# cslr_fsync register map
Vendor: Texas Instruments
Peripheral module from a debugger description file.
Registers are 32-bit, access per field, reset 0x0 unless marked. A register's access mark holds for its fields unless they carry their own. Offsets are as the file gives them; lines under a group give offsets from that group; [hi:lo] are bit positions; {n}, {i} and the like mark numbered series; 'fields as' and 'values as' point back to an identical list; <NAME> marks a mode.

## FSYNC — Frame Synchronization Peripheral
0x00 PID ro — Peripheral Identification Register{FSYNC_PID}
  [31:0] REG
0x80 ERR_INT_SRC_RAW ro — FSYNC ERR INT SRC RAW Register {FSYNC_ERR_INT_SRC_RAW}
  [14:0] ERR — Shows unmasked source state of interrupts
0x84 ERR_MASK_STAT_0 ro — FSYNC ERR MASK STATUS 0 Register {FSYNC_ERR_MASK_STAT_0}
  [14:0] ERR — Shows masked source state of interrupts
0x88 ERR_MASK_STAT_1 ro — FSYNC ERR MASK STATUS 1 Register {FSYNC_ERR_MASK_STAT_1}
  [14:0] ERR — Shows masked source state of interrupts
0x8C ERR_SET_MASK_0 — FSYNC ERR SET MASK 0 Register {FSYNC_ERR_SET_MASK_0}
  [14:0] ERR wo — Error set mask 0
0x90 ERR_SET_MASK_1 — FSYNC ERR SET MASK 1 Register {FSYNC_ERR_SET_MASK_1}
  [14:0] ERR wo — Error set mask 1
0x94 ERR_CLEAR_MASK_0 — FSYNC ERR CLEAR MASK 0 Register {FSYNC_ERR_CLEAR_MASK_0}
  [14:0] ERR wo — Error clear mask 0
0x98 ERR_CLEAR_MASK_1 — FSYNC ERR CLEAR MASK 1 Register {FSYNC_ERR_SET_MASK_1}
  [14:0] ERR wo — Error clear mask 1
0x9C ERR_INT_MASK_0 ro — FSYNC ERR INT MASK 0 Register {FSYNC_ERR_INT_MASK_0}
  [14:0] ERR — Error interrupt mask 0
0xA0 ERR_INT_MASK_1 ro — FSYNC ERR INT MASK 1 Register {FSYNC_ERR_INT_MASK_1}
  [14:0] ERR — Error interrupt mask 1
0xA4 ERR_INT_SET — FSYNC ERR INT SET Register {FSYNC_ERR_INT_SET}
  [14:0] ERR wo — Error interrupt set
0xA8 ERR_INT_CLEAR — FSYNC ERR INT CLEAR Register {FSYNC_ERR_INT_CLEAR}
  [14:0] ERR wo — Error interrupt clear
0xAC ERR_END_OF_INT — FSYNC ERR END 0F INT Register {FSYNC_ERR_END_OF_INT}
  [14:0] ERR rw — Error end of interrupt
0xB0 SCRATCH rw — FSYNC Scratch Register {FSYNC_SCRATCH}
  [31:0] SCRATCH — Dummy location for test
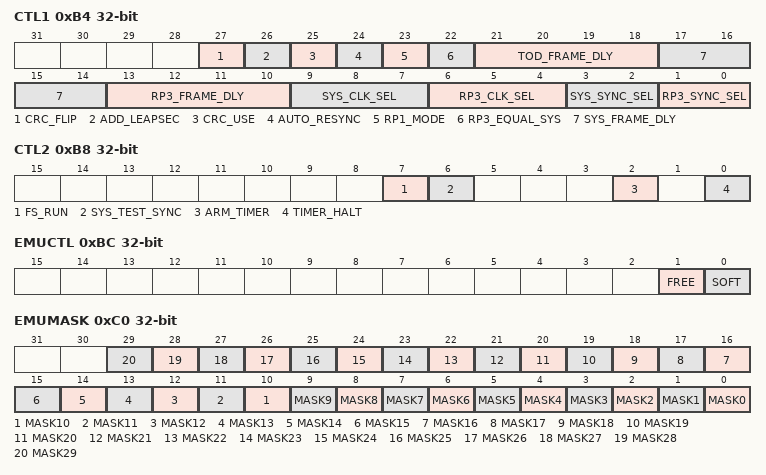
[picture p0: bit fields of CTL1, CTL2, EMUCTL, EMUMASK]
0xB4 CTL1 — FSYNC Control Register 1 {FSYNC_CTL1}
  [27] CRC_FLIP rw — Timer start
    0=MS_1ST (CRC bit 15 received first); 1=LS_1ST (CRC bit 0 received first)
  [26] ADD_LEAPSEC rw — Timer halt
    0=NO_ADD (Do not add leapseconds to TOD); 1=ADD (Add leapseconds to TOD timer)
  [25] CRC_USE rw — CRC use enable
    0=DISABLE (Use sync_burst message regardless of CRC pass/fail); 1=ENABLE (Discard sync_burst message on CRC fail)
  [24] AUTO_RESYNC rw — Automatic resync enable
    0=DISABLE (Disable auto-resync); 1=ENABLE (Enable auto-resync)
  [23] RP1_MODE rw — RP1 operation mode enable
    0=DISABLE (Disable RP1 synchronization); 1=ENABLE (Enable RP1 synchronization)
  [22] RP3_EQUAL_SYS rw — System timer only selection
    0=FALSE (System timer is separate from RP3 timer); 1=TRUE (System timer is the same as the RP3 timer)
  [21:18] TOD_FRAME_DLY rw — Time-of-Day frame syncronization delay
  [17:14] SYS_FRAME_DLY rw — System frame syncronization delay
  [13:10] RP3_FRAME_DLY rw — RP3 frame syncronization delay
  [9:7] SYS_CLK_SEL rw — System timer clock source selection
    0=MOD_CLK (Internal module clock (CPU/3)); 1=MOD_CLK3 (Module clock / 3 (CPU/9)); 2=FSYNC_CLK (Frame sync clock input); 3=UMTS_CLK (UMTS clock input); 4=TRT_CLK (TRT clock input)
  [6:4] RP3_CLK_SEL rw — RP3 timer clock source selection
    values as SYS_CLK_SEL
  [3:2] SYS_SYNC_SEL rw — System timer synchronization selection
    0=FRAME_BURST (OBSAI RP1 differential FRAME_BURST); 1=UMTS_SYNC (UMTS_SYNC input); 2=TRT (TRT input); 3=SYS_TEST (System Test input)
  [1:0] RP3_SYNC_SEL rw — RP3 timer synchronization selcetion
    values as SYS_SYNC_SEL
0xB8 CTL2 — FSYNC Control Register 2 {FSYNC_CTL2}
  [7] FS_RUN ro — FS Running
    0=NO_RUN (No effect); 1=RUN (FS run)
  [6] SYS_TEST_SYNC rw — System test sync
    0=NO_PULSE (No effect); 1=PULSE (Create internal sync pulse)
  [2] ARM_TIMER rw — Arm the RP3 timer to start when synchronization occurs
    0=NO_ARM (No effect); 1=ARM (Arm Timers)
  [0] TIMER_HALT rw
    0=NO_HALT (No effect); 1=HALT (Halt RP3 and system timers)
0xBC EMUCTL — FSYNC Emulation Control Register {FSYNC_EMUCTL}
  [1] FREE rw — Free run
    0=SUSPEND (Halt on emulation halt); 1=FREERUN (Ignore emulation halt)
  [0] SOFT rw — Soft halt
    0=SOFTHALT (Free run timers, disable some events with emu mask); 1=HARDHALT (Halt all timers and events)
0xC0 EMUMASK — FSYNC Emulation Mask Register {FSYNC_EMUMASK}
  [n] MASK{n} rw (n=0..29) — Mask for Event {n}
    0=FALSE (Do not mask event {n}); 1=TRUE (Mask event {n})
0xC4 RP1TS — FSYNC RP1 Type Select Register {FSYNC_RP1TS}
  [7:0] RP1_TYPE rw
    2=WCDMA_FDD (WCDMA or FDD); 7=CDMA2000
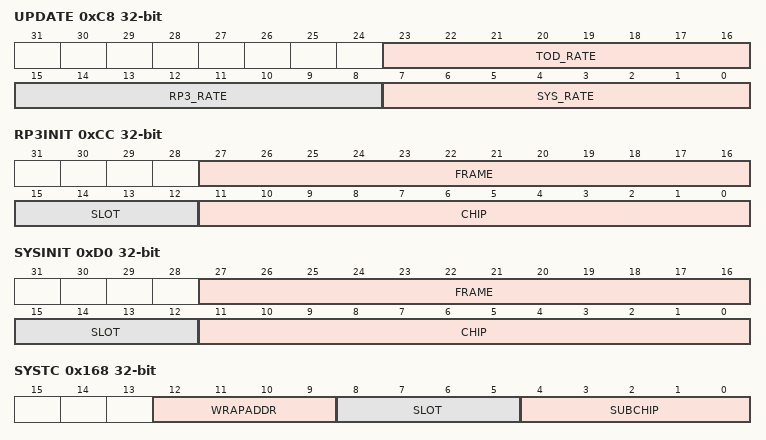
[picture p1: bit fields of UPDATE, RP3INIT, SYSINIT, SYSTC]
0xC8 UPDATE — FSYNC Update Register {FSYNC_UPDATE}
  [23:16] TOD_RATE rw — System Frame Update Rate
  [15:8] RP3_RATE rw — RP3 Frame Update Rate
  [7:0] SYS_RATE rw — TOD Frame Update Rate
0xCC RP3INIT rw — FSYNC RP3 Init Register {FSYNC_RP3INIT}
  [27:16] FRAME — System tmer frame count
  [15:12] SLOT — System timer slot count
  [11:0] CHIP — System timer chip count
0xD0 SYSINIT rw — FSYNC System Init Register {FSYNC_SYSINIT}
  fields as RP3INIT
0x100 RP3TC0 ro — FSYNC RP3 Terminal Count Entry {FSYNC_RP3TC0}
  [11:0] TCOUNT — Terminal Count RAM for chip count
0x104 RP3TC1 ro — FSYNC RP3 Terminal Count Entry {FSYNC_RP3TC1}
  [11:0] TCOUNT — Terminal Count RAM for chip count
0x108 RP3TC2 ro — FSYNC RP3 Terminal Count Entry {FSYNC_RP3TC2}
  [11:0] TCOUNT — Terminal Count RAM for chip count
0x10C RP3TC3 ro — FSYNC RP3 Terminal Count Entry {FSYNC_RP3TC3}
  [11:0] TCOUNT — Terminal Count RAM for chip count
0x110 RP3TC4 ro — FSYNC RP3 Terminal Count Entry {FSYNC_RP3TC4}
  [11:0] TCOUNT — Terminal Count RAM for chip count
0x114 RP3TC5 ro — FSYNC RP3 Terminal Count Entry {FSYNC_RP3TC5}
  [11:0] TCOUNT — Terminal Count RAM for chip count
0x118 RP3TC6 ro — FSYNC RP3 Terminal Count Entry {FSYNC_RP3TC6}
  [11:0] TCOUNT — Terminal Count RAM for chip count
0x11C RP3TC7 ro — FSYNC RP3 Terminal Count Entry {FSYNC_RP3TC7}
  [11:0] TCOUNT — Terminal Count RAM for chip count
0x120 RP3TC8 ro — FSYNC RP3 Terminal Count Entry {FSYNC_RP3TC8}
  [11:0] TCOUNT — Terminal Count RAM for chip count
0x124 RP3TC9 ro — FSYNC RP3 Terminal Count Entry {FSYNC_RP3TC9}
  [11:0] TCOUNT — Terminal Count RAM for chip count
0x128 TOD1 ro — FSYNC TOD Capture Register 1 {FSYNC_TOD1}
  [31:0] TOD_LS — TOD Capture LSBs
0x12C TOD2 ro — FSYNC TOD Capture Register2 {FSYNC_TOD2}
  [31:0] TOD_MS — TOD Capture MSBs
0x130 RP31 ro — FSYNC RP3 Capture Register 1 {FSYNC_RP31}
  [31:0] RP3_LS — RP3 Capture LSBs
0x134 RP32 ro — FSYNC RP3 Capture Register 2 {FSYNC_RP32}
  [31:0] RP3_MS — RP3 Capture MSBs
0x138 SYS1 ro — FSYNC SYS Capture Register 1 {FSYNC_SYS1}
  [31:0] SYS_LS — SYS Capture LSBs
0x13C SYS2 ro — FSYNC SYS Capture Register 2 {FSYNC_SYS2}
  [31:0] SYS_MS — SYS Capture MSBs
0x140 SYSTC0 ro — FSYNC System Terminal Count Entry {FSYNC_SYSTC0}
  [11:0] TCOUNT — Terminal Count RAM for chip count
0x144 SYSTC1 ro — FSYNC System Terminal Count Entry {FSYNC_SYSTC1}
  [11:0] TCOUNT — Terminal Count RAM for chip count
0x148 SYSTC2 ro — FSYNC System Terminal Count Entry {FSYNC_SYSTC2}
  [11:0] TCOUNT — Terminal Count RAM for chip count
0x14C SYSTC3 ro — FSYNC System Terminal Count Entry {FSYNC_SYSTC3}
  [11:0] TCOUNT — Terminal Count RAM for chip count
0x150 SYSTC4 ro — FSYNC System Terminal Count Entry {FSYNC_SYSTC4}
  [11:0] TCOUNT — Terminal Count RAM for chip count
0x154 SYSTC5 ro — FSYNC System Terminal Count Entry {FSYNC_SYSTC5}
  [11:0] TCOUNT — Terminal Count RAM for chip count
0x158 SYSTC6 ro — FSYNC System Terminal Count Entry {FSYNC_SYSTC6}
  [11:0] TCOUNT — Terminal Count RAM for chip count
0x15C SYSTC7 ro — FSYNC System Terminal Count Entry {FSYNC_SYSTC7}
  [11:0] TCOUNT — Terminal Count RAM for chip count
0x160 SYSTC8 ro — FSYNC System Terminal Count Entry {FSYNC_SYSTC8}
  [11:0] TCOUNT — Terminal Count RAM for chip count
0x164 SYSTC9 ro — FSYNC System Terminal Count Entry {FSYNC_SYSTC9}
  [11:0] TCOUNT — Terminal Count RAM for chip count
0x168 SYSTC — FSYNC System Terminal Count Register {FSYNC_SYSTC}
  [12:9] WRAPADDR rw — Chip TC RAM wrap address
  [8:5] SLOT rw
  [4:0] SUBCHIP rw — Sub-chip (input clock divider)
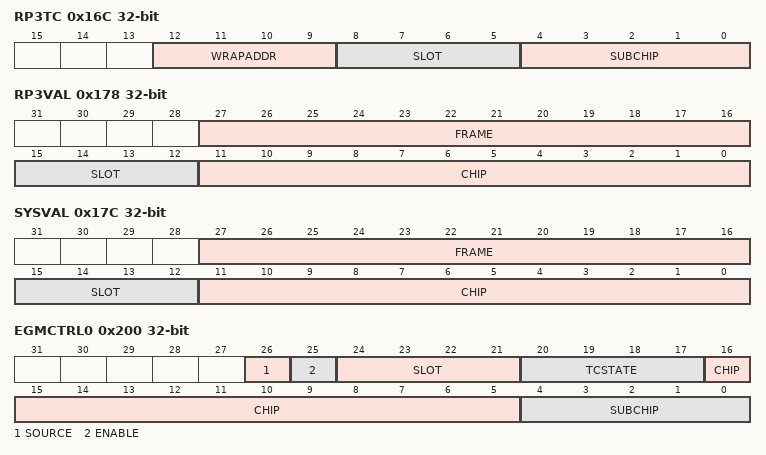
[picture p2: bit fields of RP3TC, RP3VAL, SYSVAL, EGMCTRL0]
0x16C RP3TC — FSYNC System Terminal Count Register {FSYNC_RP3TC}
  fields as SYSTC
0x170 TYPE ro — FSYNC Type Capture Register {FSYNC_TYPE}
  [7:0] TYPE — RP1 Type Capture
0x174 TODVAL ro — FSYNC TOD VAL Register {FSYNC_TODVAL}
  [31:0] VALUE — Read the current value of the TOD timer in secs
0x178 RP3VAL ro — FSYNC RP3 VAL Register {FSYNC_RP3VAL}
  fields as RP3INIT
0x17C SYSVAL ro — FSYNC System VAL Register {FSYNC_SYSVAL}
  fields as RP3INIT
0x200 EGMCTRL0 — FSYNC Mask Event Generator Control Register {FSYNC_EGMCTRL0}
  [26] SOURCE rw — Event Source
    0=SYS (System timer with system sub-chip clock); 1=RP3 (RP3 timer with RP3 sub-chip clock)
  [25] ENABLE rw — Event Enable
    0=DISABLE (Disable Event); 1=ENABLE (Enable Event)
  [24:21] SLOT rw — Slot compare value
  [20:17] TCSTATE rw — Chip TC state compare value
  [16:5] CHIP rw — Chip compare value
  [4:0] SUBCHIP rw — Sub-chip compare value
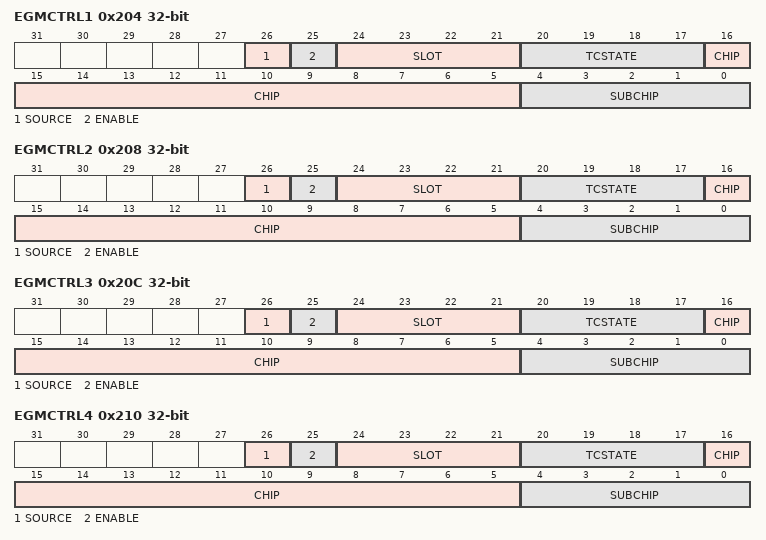
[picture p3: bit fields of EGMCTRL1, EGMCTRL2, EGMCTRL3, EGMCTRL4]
0x204 EGMCTRL1 — FSYNC Mask Event Generator Control Register {FSYNC_EGMCTRL1}
  fields as EGMCTRL0
0x208 EGMCTRL2 — FSYNC Mask Event Generator Control Register {FSYNC_EGMCTRL2}
  fields as EGMCTRL0
0x20C EGMCTRL3 — FSYNC Mask Event Generator Control Register {FSYNC_EGMCTRL3}
  fields as EGMCTRL0
0x210 EGMCTRL4 — FSYNC Mask Event Generator Control Register {FSYNC_EGMCTRL4}
  fields as EGMCTRL0
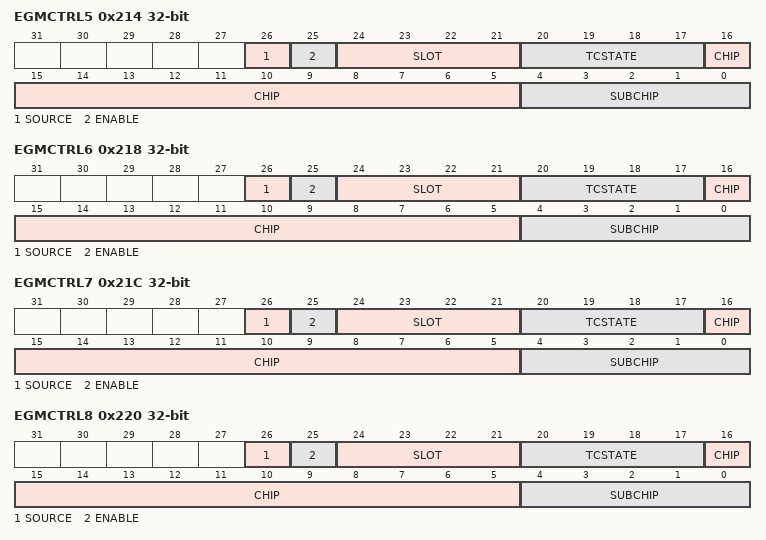
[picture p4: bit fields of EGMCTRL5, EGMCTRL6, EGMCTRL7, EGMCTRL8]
0x214 EGMCTRL5 — FSYNC Mask Event Generator Control Register {FSYNC_EGMCTRL5}
  fields as EGMCTRL0
0x218 EGMCTRL6 — FSYNC Mask Event Generator Control Register {FSYNC_EGMCTRL6}
  fields as EGMCTRL0
0x21C EGMCTRL7 — FSYNC Mask Event Generator Control Register {FSYNC_EGMCTRL7}
  fields as EGMCTRL0
0x220 EGMCTRL8 — FSYNC Mask Event Generator Control Register {FSYNC_EGMCTRL8}
  fields as EGMCTRL0
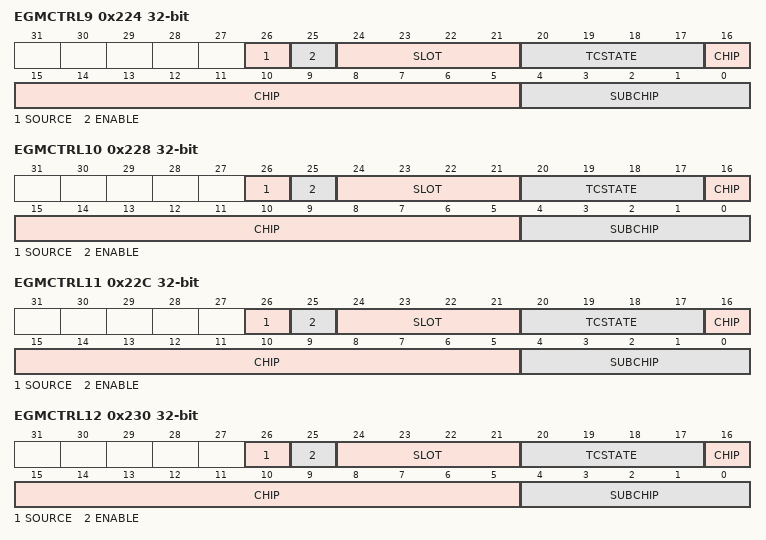
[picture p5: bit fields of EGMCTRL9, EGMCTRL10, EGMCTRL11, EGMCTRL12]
0x224 EGMCTRL9 — FSYNC Mask Event Generator Control Register {FSYNC_EGMCTRL9}
  fields as EGMCTRL0
0x228 EGMCTRL10 — FSYNC Mask Event Generator Control Register {FSYNC_EGMCTRL10}
  fields as EGMCTRL0
0x22C EGMCTRL11 — FSYNC Mask Event Generator Control Register {FSYNC_EGMCTRL11}
  fields as EGMCTRL0
0x230 EGMCTRL12 — FSYNC Mask Event Generator Control Register {FSYNC_EGMCTRL12}
  fields as EGMCTRL0
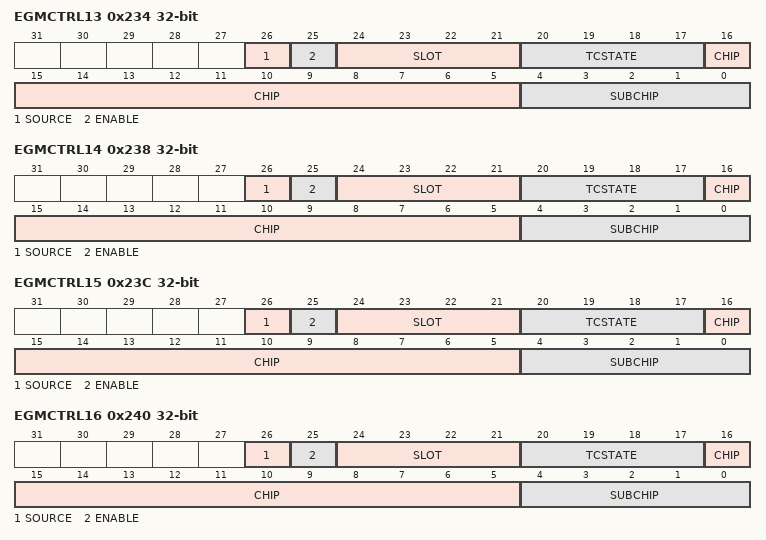
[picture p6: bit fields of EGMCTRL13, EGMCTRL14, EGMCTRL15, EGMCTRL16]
0x234 EGMCTRL13 — FSYNC Mask Event Generator Control Register {FSYNC_EGMCTRL13}
  fields as EGMCTRL0
0x238 EGMCTRL14 — FSYNC Mask Event Generator Control Register {FSYNC_EGMCTRL14}
  fields as EGMCTRL0
0x23C EGMCTRL15 — FSYNC Mask Event Generator Control Register {FSYNC_EGMCTRL15}
  fields as EGMCTRL0
0x240 EGMCTRL16 — FSYNC Mask Event Generator Control Register {FSYNC_EGMCTRL16}
  fields as EGMCTRL0
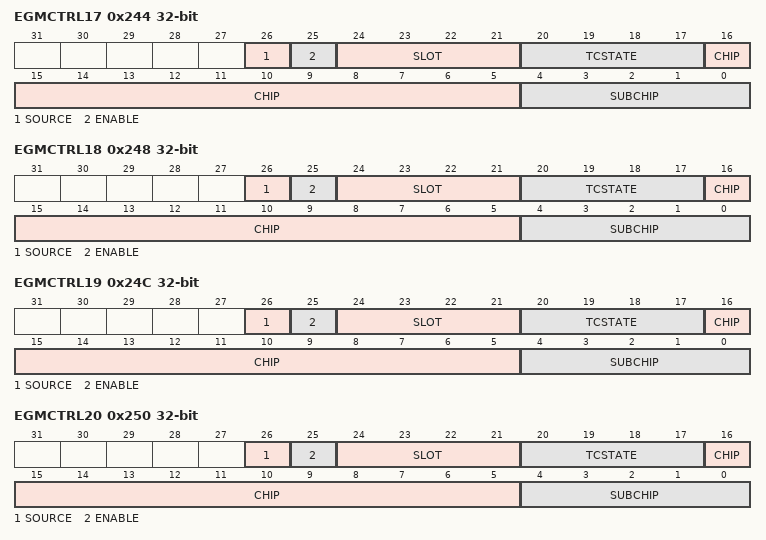
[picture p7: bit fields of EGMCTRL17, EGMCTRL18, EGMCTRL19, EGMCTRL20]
0x244 EGMCTRL17 — FSYNC Mask Event Generator Control Register {FSYNC_EGMCTRL17}
  fields as EGMCTRL0
0x248 EGMCTRL18 — FSYNC Mask Event Generator Control Register {FSYNC_EGMCTRL18}
  fields as EGMCTRL0
0x24C EGMCTRL19 — FSYNC Mask Event Generator Control Register {FSYNC_EGMCTRL19}
  fields as EGMCTRL0
0x250 EGMCTRL20 — FSYNC Mask Event Generator Control Register {FSYNC_EGMCTRL20}
  fields as EGMCTRL0
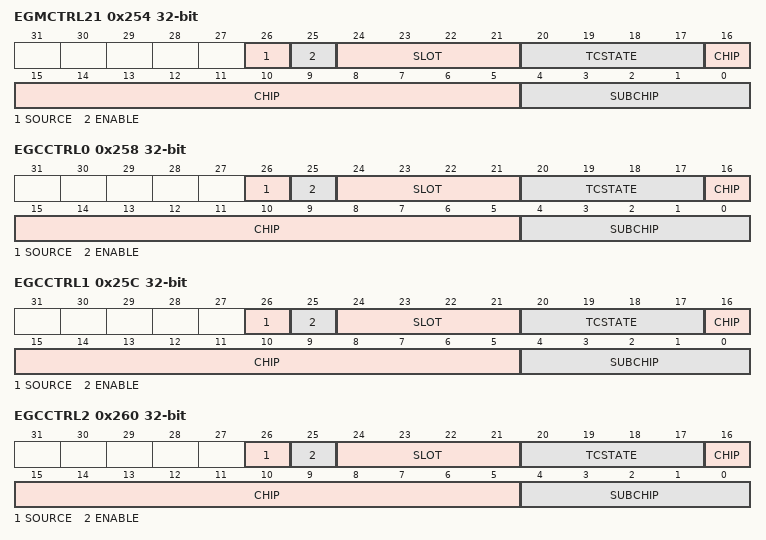
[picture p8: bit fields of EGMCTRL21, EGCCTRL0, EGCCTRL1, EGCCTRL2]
0x254 EGMCTRL21 — FSYNC Mask Event Generator Control Register {FSYNC_EGMCTRL21}
  fields as EGMCTRL0
0x258 EGCCTRL0 — FSYNC Counter Event Generator Control Register {FSYNC_EGCCTRL0}
  fields as EGMCTRL0
0x25C EGCCTRL1 — FSYNC Counter Event Generator Control Register {FSYNC_EGCCTRL1}
  fields as EGMCTRL0
0x260 EGCCTRL2 — FSYNC Counter Event Generator Control Register {FSYNC_EGCCTRL2}
  fields as EGMCTRL0
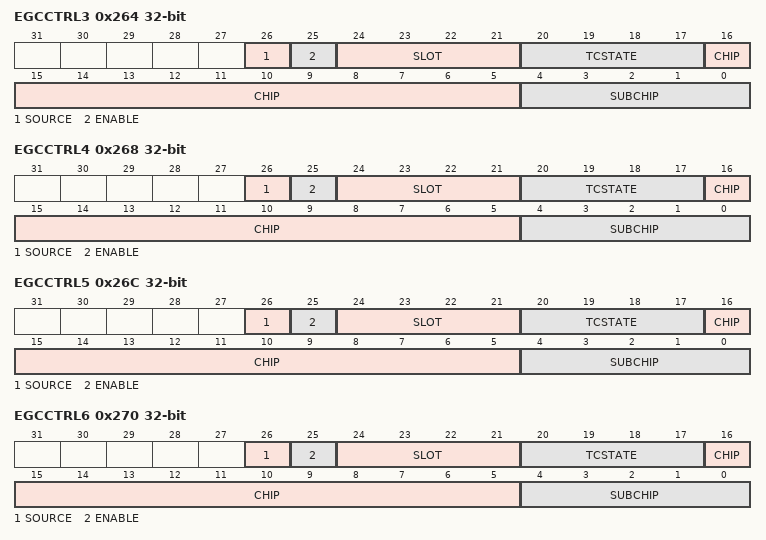
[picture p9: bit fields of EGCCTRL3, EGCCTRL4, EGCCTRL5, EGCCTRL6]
0x264 EGCCTRL3 — FSYNC Counter Event Generator Control Register {FSYNC_EGCCTRL3}
  fields as EGMCTRL0
0x268 EGCCTRL4 — FSYNC Counter Event Generator Control Register {FSYNC_EGCCTRL4}
  fields as EGMCTRL0
0x26C EGCCTRL5 — FSYNC Counter Event Generator Control Register {FSYNC_EGCCTRL5}
  fields as EGMCTRL0
0x270 EGCCTRL6 — FSYNC Counter Event Generator Control Register {FSYNC_EGCCTRL6}
  fields as EGMCTRL0
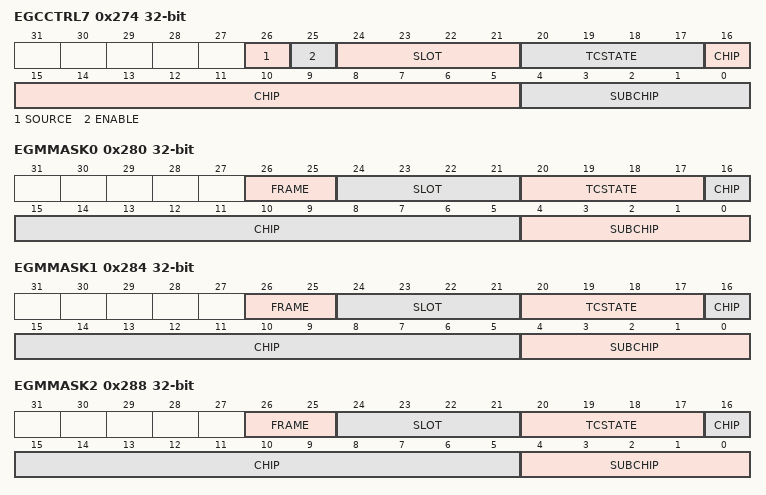
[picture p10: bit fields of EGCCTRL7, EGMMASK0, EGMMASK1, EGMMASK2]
0x274 EGCCTRL7 — FSYNC Counter Event Generator Control Register {FSYNC_EGCCTRL7}
  fields as EGMCTRL0
0x280 EGMMASK0 — FSYNC Mask Event Generator Mask {FSYNC_EGMMASK0}
  [26:25] FRAME rw
  [24:21] SLOT rw
  [20:17] TCSTATE rw — Chip TC state
  [16:5] CHIP rw
  [4:0] SUBCHIP rw
0x284 EGMMASK1 — FSYNC Mask Event Generator Mask {FSYNC_EGMMASK1}
  fields as EGMMASK0
0x288 EGMMASK2 — FSYNC Mask Event Generator Mask {FSYNC_EGMMASK2}
  fields as EGMMASK0
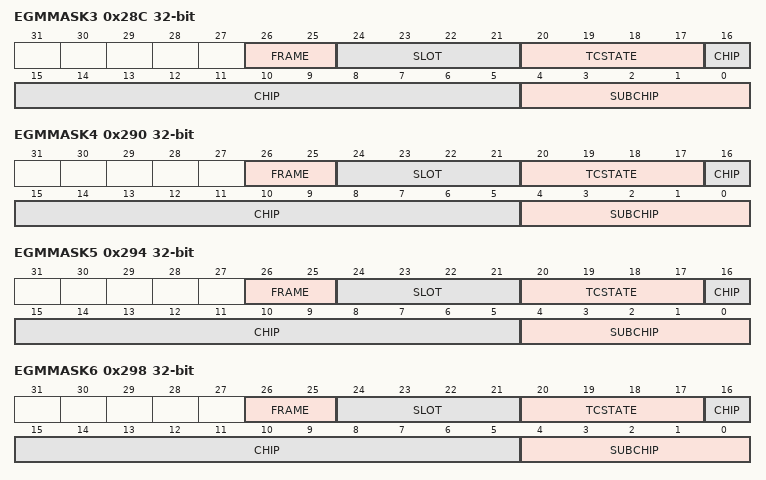
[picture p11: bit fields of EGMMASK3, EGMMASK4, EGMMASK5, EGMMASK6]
0x28C EGMMASK3 — FSYNC Mask Event Generator Mask {FSYNC_EGMMASK3}
  fields as EGMMASK0
0x290 EGMMASK4 — FSYNC Mask Event Generator Mask {FSYNC_EGMMASK4}
  fields as EGMMASK0
0x294 EGMMASK5 — FSYNC Mask Event Generator Mask {FSYNC_EGMMASK5}
  fields as EGMMASK0
0x298 EGMMASK6 — FSYNC Mask Event Generator Mask {FSYNC_EGMMASK6}
  fields as EGMMASK0
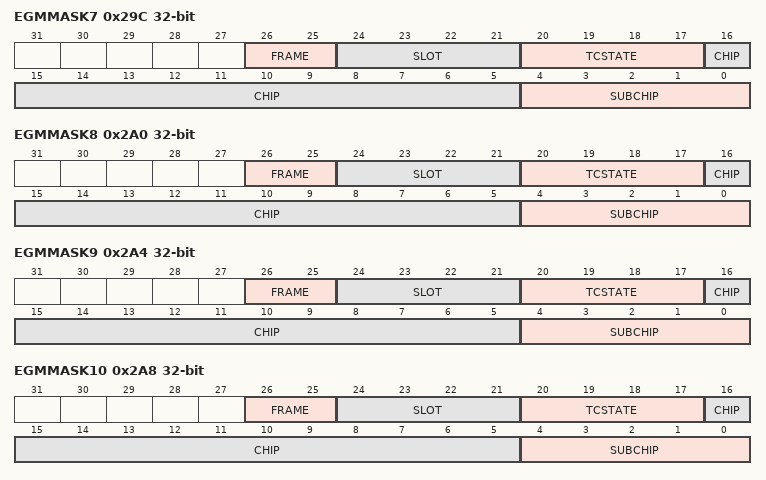
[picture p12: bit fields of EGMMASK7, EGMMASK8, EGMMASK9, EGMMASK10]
0x29C EGMMASK7 — FSYNC Mask Event Generator Mask {FSYNC_EGMMASK7}
  fields as EGMMASK0
0x2A0 EGMMASK8 — FSYNC Mask Event Generator Mask {FSYNC_EGMMASK8}
  fields as EGMMASK0
0x2A4 EGMMASK9 — FSYNC Mask Event Generator Mask {FSYNC_EGMMASK9}
  fields as EGMMASK0
0x2A8 EGMMASK10 — FSYNC Mask Event Generator Mask {FSYNC_EGMMASK10}
  fields as EGMMASK0
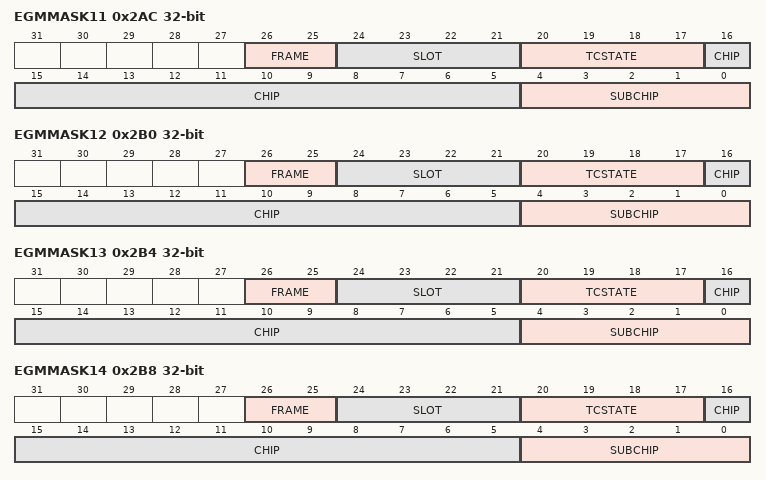
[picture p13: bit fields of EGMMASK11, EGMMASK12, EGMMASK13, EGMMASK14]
0x2AC EGMMASK11 — FSYNC Mask Event Generator Mask {FSYNC_EGMMASK11}
  fields as EGMMASK0
0x2B0 EGMMASK12 — FSYNC Mask Event Generator Mask {FSYNC_EGMMASK12}
  fields as EGMMASK0
0x2B4 EGMMASK13 — FSYNC Mask Event Generator Mask {FSYNC_EGMMASK13}
  fields as EGMMASK0
0x2B8 EGMMASK14 — FSYNC Mask Event Generator Mask {FSYNC_EGMMASK14}
  fields as EGMMASK0
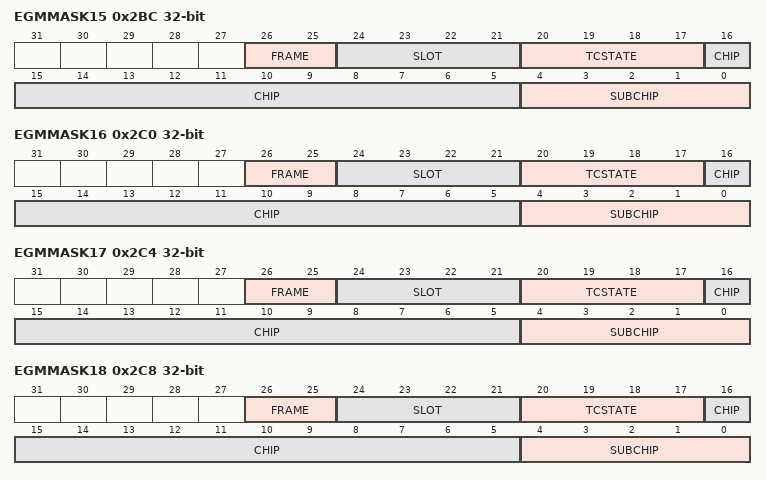
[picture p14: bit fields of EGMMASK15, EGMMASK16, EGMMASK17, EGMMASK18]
0x2BC EGMMASK15 — FSYNC Mask Event Generator Mask {FSYNC_EGMMASK15}
  fields as EGMMASK0
0x2C0 EGMMASK16 — FSYNC Mask Event Generator Mask {FSYNC_EGMMASK16}
  fields as EGMMASK0
0x2C4 EGMMASK17 — FSYNC Mask Event Generator Mask {FSYNC_EGMMASK17}
  fields as EGMMASK0
0x2C8 EGMMASK18 — FSYNC Mask Event Generator Mask {FSYNC_EGMMASK18}
  fields as EGMMASK0
0x2CC EGMMASK19 — FSYNC Mask Event Generator Mask {FSYNC_EGMMASK19}
  fields as EGMMASK0
0x2D0 EGMMASK20 — FSYNC Mask Event Generator Mask {FSYNC_EGMMASK20}
  fields as EGMMASK0
0x2D4 EGMMASK21 — FSYNC Mask Event Generator Mask {FSYNC_EGMMASK21}
  fields as EGMMASK0
0x300 EGMOFFSET0 — FSYNC Mask Event Generator Offset Value {FSYNC_EGMOFFSET0}
  fields as EGMMASK0
0x304 EGMOFFSET1 — FSYNC Mask Event Generator Offset Value {FSYNC_EGMOFFSET1}
  fields as EGMMASK0
0x308 EGMOFFSET2 — FSYNC Mask Event Generator Offset Value {FSYNC_EGMOFFSET2}
  fields as EGMMASK0
0x30C EGMOFFSET3 — FSYNC Mask Event Generator Offset Value {FSYNC_EGMOFFSET3}
  fields as EGMMASK0
0x310 EGMOFFSET4 — FSYNC Mask Event Generator Offset Value {FSYNC_EGMOFFSET4}
  fields as EGMMASK0
0x314 EGMOFFSET5 — FSYNC Mask Event Generator Offset Value {FSYNC_EGMOFFSET5}
  fields as EGMMASK0
0x318 EGMOFFSET6 — FSYNC Mask Event Generator Offset Value {FSYNC_EGMOFFSET6}
  fields as EGMMASK0
0x31C EGMOFFSET7 — FSYNC Mask Event Generator Offset Value {FSYNC_EGMOFFSET7}
  fields as EGMMASK0
0x320 EGMOFFSET8 — FSYNC Mask Event Generator Offset Value {FSYNC_EGMOFFSET8}
  fields as EGMMASK0
0x324 EGMOFFSET9 — FSYNC Mask Event Generator Offset Value {FSYNC_EGMOFFSET9}
  fields as EGMMASK0
0x328 EGMOFFSET10 — FSYNC Mask Event Generator Offset Value {FSYNC_EGMOFFSET10}
  fields as EGMMASK0
0x32C EGMOFFSET11 — FSYNC Mask Event Generator Offset Value {FSYNC_EGMOFFSET11}
  fields as EGMMASK0
0x330 EGMOFFSET12 — FSYNC Mask Event Generator Offset Value {FSYNC_EGMOFFSET12}
  fields as EGMMASK0
0x334 EGMOFFSET13 — FSYNC Mask Event Generator Offset Value {FSYNC_EGMOFFSET13}
  fields as EGMMASK0
0x338 EGMOFFSET14 — FSYNC Mask Event Generator Offset Value {FSYNC_EGMOFFSET14}
  fields as EGMMASK0
0x33C EGMOFFSET15 — FSYNC Mask Event Generator Offset Value {FSYNC_EGMOFFSET15}
  fields as EGMMASK0
0x340 EGMOFFSET16 — FSYNC Mask Event Generator Offset Value {FSYNC_EGMOFFSET16}
  fields as EGMMASK0
0x344 EGMOFFSET17 — FSYNC Mask Event Generator Offset Value {FSYNC_EGMOFFSET17}
  fields as EGMMASK0
0x348 EGMOFFSET18 — FSYNC Mask Event Generator Offset Value {FSYNC_EGMOFFSET18}
  fields as EGMMASK0
0x34C EGMOFFSET19 — FSYNC Mask Event Generator Offset Value {FSYNC_EGMOFFSET19}
  fields as EGMMASK0
0x350 EGMOFFSET20 — FSYNC Mask Event Generator Offset Value {FSYNC_EGMOFFSET20}
  fields as EGMMASK0
0x354 EGMOFFSET21 — FSYNC Mask Event Generator Offset Value {FSYNC_EGMOFFSET21}
  fields as EGMMASK0
0x358 EGCTCOUNT0 — FSYNC Counter Event Generator Control Register {FSYNC_EGMCTCOUNT}
  [26:0] TCOUNT rw — Terminal count
0x35C EGCTCOUNT1 — FSYNC Counter Event Generator Control Register {FSYNC_EGMCTCOUNT}
  [26:0] TCOUNT rw — Terminal count
0x360 EGCTCOUNT2 — FSYNC Counter Event Generator Control Register {FSYNC_EGMCTCOUNT}
  [26:0] TCOUNT rw — Terminal count
0x364 EGCTCOUNT3 — FSYNC Counter Event Generator Control Register {FSYNC_EGMCTCOUNT}
  [26:0] TCOUNT rw — Terminal count
0x368 EGCTCOUNT4 — FSYNC Counter Event Generator Control Register {FSYNC_EGMCTCOUNT}
  [26:0] TCOUNT rw — Terminal count
0x36C EGCTCOUNT5 — FSYNC Counter Event Generator Control Register {FSYNC_EGMCTCOUNT}
  [26:0] TCOUNT rw — Terminal count
0x370 EGCTCOUNT6 — FSYNC Counter Event Generator Control Register {FSYNC_EGMCTCOUNT}
  [26:0] TCOUNT rw — Terminal count
0x374 EGCTCOUNT7 — FSYNC Counter Event Generator Control Register {FSYNC_EGMCTCOUNT}
  [26:0] TCOUNT rw — Terminal count
0x380 EVTFORCE access not given — FSYNC Event Force Register {FSYNC_EVTFORCE}
  [31:30] Reserved — (access N)
  [n] EVT{n} wo (n=0..29) — Force Event {n}
    0=NO_FORCE (No effect); 1=FORCE (Force event)
